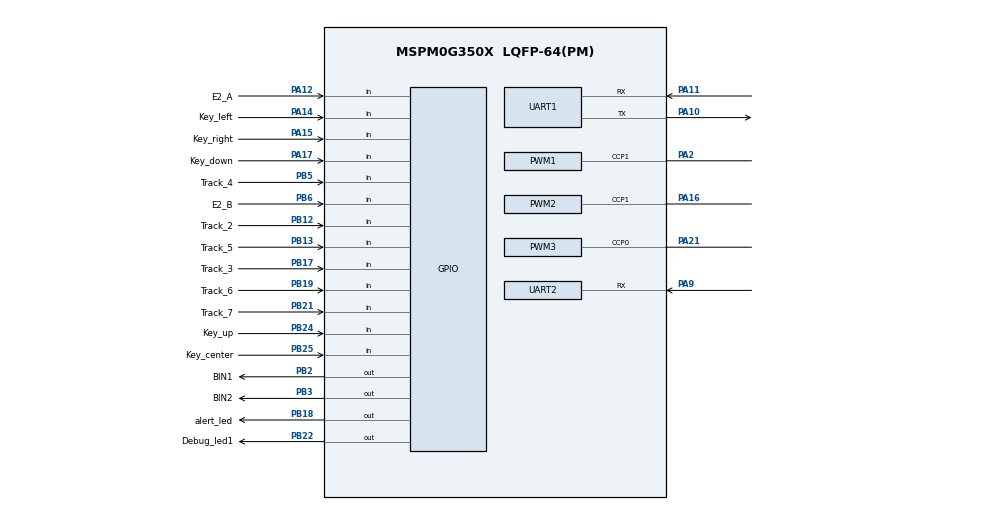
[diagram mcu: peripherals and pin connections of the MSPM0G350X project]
/**
 * @cliArgs --device "MSPM0G350X" --part "Default" --package "LQFP-64(PM)" --product "mspm0_sdk@2.04.00.06"
 * @versions {"tool":"1.23.1+4034"}
 */

/**
 * Import the modules used in this configuration.
 */
const GPIO    = scripting.addModule("/ti/driverlib/GPIO", {}, false);
const GPIO1   = GPIO.addInstance();
const GPIO2   = GPIO.addInstance();
const GPIO3   = GPIO.addInstance();
const GPIO4   = GPIO.addInstance();
const GPIO5   = GPIO.addInstance();
const GPIO6   = GPIO.addInstance();
const PWM     = scripting.addModule("/ti/driverlib/PWM", {}, false);
const PWM1    = PWM.addInstance();
const PWM2    = PWM.addInstance();
const PWM3    = PWM.addInstance();
const SYSCTL  = scripting.addModule("/ti/driverlib/SYSCTL");
const SYSTICK = scripting.addModule("/ti/driverlib/SYSTICK");
const TIMER   = scripting.addModule("/ti/driverlib/TIMER", {}, false);
const TIMER1  = TIMER.addInstance();
const TIMER2  = TIMER.addInstance();
const TIMER3  = TIMER.addInstance();
const TIMER4  = TIMER.addInstance();
const UART    = scripting.addModule("/ti/driverlib/UART", {}, false);
const UART1   = UART.addInstance();
const UART2   = UART.addInstance();

/**
 * Write custom configuration values to the imported modules.
 */
const divider9       = system.clockTree["UDIV"];
divider9.divideValue = 2;

const multiplier2         = system.clockTree["PLL_QDIV"];
multiplier2.multiplyValue = 4;

const mux4       = system.clockTree["EXHFMUX"];
mux4.inputSelect = "EXHFMUX_XTAL";

const mux8       = system.clockTree["HSCLKMUX"];
mux8.inputSelect = "HSCLKMUX_SYSPLL0";

const mux12       = system.clockTree["SYSPLLMUX"];
mux12.inputSelect = "zSYSPLLMUX_HFCLK";

const pinFunction4        = system.clockTree["HFXT"];
pinFunction4.enable       = true;
pinFunction4.HFCLKMonitor = true;
pinFunction4.inputFreq    = 40;
pinFunction4.HFXTStartup  = 10;

GPIO1.$name                              = "Debug_led";
GPIO1.port                               = "PORTB";
GPIO1.associatedPins[0].$name            = "Debug_led1";
GPIO1.associatedPins[0].ioStructure      = "SD";
GPIO1.associatedPins[0].assignedPin      = "22";
GPIO1.associatedPins[0].internalResistor = "PULL_DOWN";
GPIO1.associatedPins[0].pin.$assign      = "PB22";

const Board = scripting.addModule("/ti/driverlib/Board", {}, false);

GPIO2.$name                              = "Debug_key";
GPIO2.associatedPins.create(5);
GPIO2.associatedPins[0].$name            = "Key_center";
GPIO2.associatedPins[0].direction        = "INPUT";
GPIO2.associatedPins[0].ioStructure      = "SD";
GPIO2.associatedPins[0].assignedPort     = "PORTB";
GPIO2.associatedPins[0].assignedPin      = "25";
GPIO2.associatedPins[0].internalResistor = "PULL_UP";
GPIO2.associatedPins[0].invert           = "ENABLE";
GPIO2.associatedPins[0].pin.$assign      = "PB25";
GPIO2.associatedPins[1].invert           = "ENABLE";
GPIO2.associatedPins[1].assignedPort     = "PORTA";
GPIO2.associatedPins[1].direction        = "INPUT";
GPIO2.associatedPins[1].assignedPin      = "14";
GPIO2.associatedPins[1].ioStructure      = "HS";
GPIO2.associatedPins[1].internalResistor = "PULL_UP";
GPIO2.associatedPins[1].$name            = "Key_left";
GPIO2.associatedPins[1].pin.$assign      = "PA14";
GPIO2.associatedPins[2].direction        = "INPUT";
GPIO2.associatedPins[2].ioStructure      = "SD";
GPIO2.associatedPins[2].assignedPort     = "PORTA";
GPIO2.associatedPins[2].assignedPin      = "15";
GPIO2.associatedPins[2].internalResistor = "PULL_UP";
GPIO2.associatedPins[2].invert           = "ENABLE";
GPIO2.associatedPins[2].$name            = "Key_right";
GPIO2.associatedPins[2].pin.$assign      = "PA15";
GPIO2.associatedPins[3].direction        = "INPUT";
GPIO2.associatedPins[3].assignedPort     = "PORTA";
GPIO2.associatedPins[3].assignedPin      = "17";
GPIO2.associatedPins[3].internalResistor = "PULL_UP";
GPIO2.associatedPins[3].invert           = "ENABLE";
GPIO2.associatedPins[3].$name            = "Key_down";
GPIO2.associatedPins[3].pin.$assign      = "PA17";
GPIO2.associatedPins[4].$name            = "Key_up";
GPIO2.associatedPins[4].direction        = "INPUT";
GPIO2.associatedPins[4].internalResistor = "PULL_UP";
GPIO2.associatedPins[4].invert           = "ENABLE";
GPIO2.associatedPins[4].assignedPort     = "PORTB";
GPIO2.associatedPins[4].assignedPin      = "24";
GPIO2.associatedPins[4].ioStructure      = "SD";
GPIO2.associatedPins[4].pin.$assign      = "PB24";

GPIO3.$name                          = "Motor_DIR";
GPIO3.associatedPins.create(4);
GPIO3.associatedPins[0].initialValue = "SET";
GPIO3.associatedPins[0].ioStructure  = "SD";
GPIO3.associatedPins[0].assignedPort = "PORTB";
GPIO3.associatedPins[0].assignedPin  = "15";
GPIO3.associatedPins[0].$name        = "AIN2";
GPIO3.associatedPins[1].initialValue = "SET";
GPIO3.associatedPins[1].assignedPort = "PORTB";
GPIO3.associatedPins[1].assignedPin  = "16";
GPIO3.associatedPins[1].$name        = "AIN1";
GPIO3.associatedPins[2].$name        = "BIN1";
GPIO3.associatedPins[2].initialValue = "SET";
GPIO3.associatedPins[2].ioStructure  = "SD";
GPIO3.associatedPins[2].assignedPort = "PORTB";
GPIO3.associatedPins[2].assignedPin  = "02";
GPIO3.associatedPins[2].pin.$assign  = "PB2";
GPIO3.associatedPins[3].$name        = "BIN2";
GPIO3.associatedPins[3].initialValue = "SET";
GPIO3.associatedPins[3].ioStructure  = "SD";
GPIO3.associatedPins[3].assignedPort = "PORTB";
GPIO3.associatedPins[3].assignedPin  = "03";
GPIO3.associatedPins[3].pin.$assign  = "PB3";

GPIO4.$name                               = "Encoder";
GPIO4.associatedPins.create(4);
GPIO4.associatedPins[0].direction         = "INPUT";
GPIO4.associatedPins[0].assignedPort      = "PORTB";
GPIO4.associatedPins[0].assignedPin       = "23";
GPIO4.associatedPins[0].interruptEn       = true;
GPIO4.associatedPins[0].interruptPriority = "0";
GPIO4.associatedPins[0].polarity          = "RISE";
GPIO4.associatedPins[0].$name             = "E1_B";
GPIO4.associatedPins[1].direction         = "INPUT";
GPIO4.associatedPins[1].assignedPort      = "PORTB";
GPIO4.associatedPins[1].assignedPin       = "27";
GPIO4.associatedPins[1].interruptEn       = true;
GPIO4.associatedPins[1].interruptPriority = "0";
GPIO4.associatedPins[1].polarity          = "RISE";
GPIO4.associatedPins[1].$name             = "E1_A";
GPIO4.associatedPins[2].$name             = "E2_A";
GPIO4.associatedPins[2].direction         = "INPUT";
GPIO4.associatedPins[2].assignedPort      = "PORTA";
GPIO4.associatedPins[2].assignedPin       = "12";
GPIO4.associatedPins[2].interruptEn       = true;
GPIO4.associatedPins[2].interruptPriority = "0";
GPIO4.associatedPins[2].polarity          = "RISE";
GPIO4.associatedPins[2].pin.$assign       = "PA12";
GPIO4.associatedPins[3].$name             = "E2_B";
GPIO4.associatedPins[3].direction         = "INPUT";
GPIO4.associatedPins[3].assignedPort      = "PORTB";
GPIO4.associatedPins[3].assignedPin       = "6";
GPIO4.associatedPins[3].interruptEn       = true;
GPIO4.associatedPins[3].interruptPriority = "0";
GPIO4.associatedPins[3].polarity          = "RISE";
GPIO4.associatedPins[3].pin.$assign       = "PB6";

GPIO5.$name                              = "Track";
GPIO5.port                               = "PORTB";
GPIO5.associatedPins.create(7);
GPIO5.associatedPins[0].direction        = "INPUT";
GPIO5.associatedPins[0].assignedPin      = "04";
GPIO5.associatedPins[0].$name            = "Track_1";
GPIO5.associatedPins[0].internalResistor = "PULL_UP";
GPIO5.associatedPins[1].$name            = "Track_2";
GPIO5.associatedPins[1].direction        = "INPUT";
GPIO5.associatedPins[1].assignedPin      = "12";
GPIO5.associatedPins[1].internalResistor = "PULL_UP";
GPIO5.associatedPins[1].pin.$assign      = "PB12";
GPIO5.associatedPins[2].$name            = "Track_3";
GPIO5.associatedPins[2].direction        = "INPUT";
GPIO5.associatedPins[2].assignedPin      = "17";
GPIO5.associatedPins[2].internalResistor = "PULL_UP";
GPIO5.associatedPins[2].pin.$assign      = "PB17";
GPIO5.associatedPins[3].$name            = "Track_4";
GPIO5.associatedPins[3].direction        = "INPUT";
GPIO5.associatedPins[3].assignedPin      = "5";
GPIO5.associatedPins[3].internalResistor = "PULL_UP";
GPIO5.associatedPins[3].pin.$assign      = "PB5";
GPIO5.associatedPins[4].$name            = "Track_5";
GPIO5.associatedPins[4].direction        = "INPUT";
GPIO5.associatedPins[4].assignedPin      = "13";
GPIO5.associatedPins[4].internalResistor = "PULL_UP";
GPIO5.associatedPins[4].pin.$assign      = "PB13";
GPIO5.associatedPins[5].$name            = "Track_6";
GPIO5.associatedPins[5].direction        = "INPUT";
GPIO5.associatedPins[5].internalResistor = "PULL_DOWN";
GPIO5.associatedPins[5].assignedPin      = "19";
GPIO5.associatedPins[5].pin.$assign      = "PB19";
GPIO5.associatedPins[6].$name            = "Track_7";
GPIO5.associatedPins[6].direction        = "INPUT";
GPIO5.associatedPins[6].assignedPin      = "21";
GPIO5.associatedPins[6].pin.$assign      = "PB21";

GPIO6.$name                          = "Alert_led";
GPIO6.associatedPins[0].$name        = "alert_led";
GPIO6.associatedPins[0].assignedPort = "PORTB";
GPIO6.associatedPins[0].assignedPin  = "18";
GPIO6.associatedPins[0].pin.$assign  = "PB18";

PWM1.ccIndex                            = [1];
PWM1.$name                              = "Motor_A";
PWM1.timerStartTimer                    = true;
PWM1.timerCount                         = 10001;
PWM1.ccp1PinConfig.direction            = scripting.forceWrite("OUTPUT");
PWM1.ccp1PinConfig.hideOutputInversion  = scripting.forceWrite(false);
PWM1.ccp1PinConfig.onlyInternalResistor = scripting.forceWrite(false);
PWM1.ccp1PinConfig.passedPeripheralType = scripting.forceWrite("Digital");
PWM1.ccp1PinConfig.$name                = "ti_driverlib_gpio_GPIOPinGeneric3";
PWM1.peripheral.$assign                 = "TIMG7";
PWM1.peripheral.ccp1Pin.$assign         = "PA2";
PWM1.PWM_CHANNEL_1.$name                = "ti_driverlib_pwm_PWMTimerCC0";
PWM1.PWM_CHANNEL_1.invert               = true;

PWM2.$name                              = "Motor_B";
PWM2.ccIndex                            = [1];
PWM2.timerStartTimer                    = true;
PWM2.timerCount                         = 10001;
PWM2.ccp1PinConfig.direction            = scripting.forceWrite("OUTPUT");
PWM2.ccp1PinConfig.hideOutputInversion  = scripting.forceWrite(false);
PWM2.ccp1PinConfig.onlyInternalResistor = scripting.forceWrite(false);
PWM2.ccp1PinConfig.passedPeripheralType = scripting.forceWrite("Digital");
PWM2.ccp1PinConfig.$name                = "ti_driverlib_gpio_GPIOPinGeneric2";
PWM2.peripheral.$assign                 = "TIMA1";
PWM2.peripheral.ccp1Pin.$assign         = "PA16";
PWM2.PWM_CHANNEL_1.$name                = "ti_driverlib_pwm_PWMTimerCC1";
PWM2.PWM_CHANNEL_1.invert               = true;

PWM3.$name                              = "Debug_Buzzer";
PWM3.ccIndex                            = [0];
PWM3.timerStartTimer                    = true;
PWM3.timerCount                         = 65535;
PWM3.PWM_CHANNEL_0.$name                = "ti_driverlib_pwm_PWMTimerCC2";
PWM3.PWM_CHANNEL_0.invert               = true;
PWM3.ccp0PinConfig.$name                = "ti_driverlib_gpio_GPIOPinGeneric4";
PWM3.ccp0PinConfig.direction            = scripting.forceWrite("OUTPUT");
PWM3.ccp0PinConfig.hideOutputInversion  = scripting.forceWrite(false);
PWM3.ccp0PinConfig.onlyInternalResistor = scripting.forceWrite(false);
PWM3.ccp0PinConfig.passedPeripheralType = scripting.forceWrite("Digital");
PWM3.peripheral.$assign                 = "TIMA0";
PWM3.peripheral.ccp0Pin.$assign         = "PA21";

SYSCTL.forceDefaultClkConfig = true;
SYSCTL.clockTreeEn           = true;

SYSTICK.periodEnable      = true;
SYSTICK.interruptEnable   = true;
SYSTICK.interruptPriority = "0";
SYSTICK.systickEnable     = true;
SYSTICK.period            = 80000;

TIMER1.$name             = "Key_task";
TIMER1.timerPeriod       = "20 ms";
TIMER1.timerStartTimer   = true;
TIMER1.interrupts        = ["ZERO"];
TIMER1.interruptPriority = "3";
TIMER1.timerMode         = "PERIODIC";
TIMER1.timerClkDiv       = 8;

TIMER2.$name             = "PidSpeed_Task";
TIMER2.timerClkDiv       = 8;
TIMER2.timerStartTimer   = true;
TIMER2.interrupts        = ["ZERO"];
TIMER2.interruptPriority = "1";
TIMER2.timerMode         = "PERIODIC";
TIMER2.timerClkPrescale  = 100;
TIMER2.timerPeriod       = "20 ms";

TIMER3.$name             = "PidTrack_Task";
TIMER3.timerMode         = "PERIODIC";
TIMER3.timerPeriod       = "50 ms";
TIMER3.timerClkDiv       = 8;
TIMER3.timerClkPrescale  = 10;
TIMER3.timerStartTimer   = true;
TIMER3.interrupts        = ["ZERO"];
TIMER3.interruptPriority = "1";

TIMER4.$name              = "PidAngle_Task";
TIMER4.timerMode          = "PERIODIC";
TIMER4.timerClkPrescale   = 10;
TIMER4.timerClkDiv        = 8;
TIMER4.timerStartTimer    = true;
TIMER4.interrupts         = ["ZERO"];
TIMER4.interruptPriority  = "1";
TIMER4.timerPeriod        = "50 ms";
TIMER4.peripheral.$assign = "TIMG0";

UART1.$name                            = "Debug_UART";
UART1.enabledInterrupts                = ["RX"];
UART1.peripheral.$assign               = "UART0";
UART1.peripheral.rxPin.$assign         = "PA11";
UART1.peripheral.txPin.$assign         = "PA10";
UART1.txPinConfig.direction            = scripting.forceWrite("OUTPUT");
UART1.txPinConfig.hideOutputInversion  = scripting.forceWrite(false);
UART1.txPinConfig.onlyInternalResistor = scripting.forceWrite(false);
UART1.txPinConfig.passedPeripheralType = scripting.forceWrite("Digital");
UART1.txPinConfig.$name                = "ti_driverlib_gpio_GPIOPinGeneric0";
UART1.rxPinConfig.hideOutputInversion  = scripting.forceWrite(false);
UART1.rxPinConfig.onlyInternalResistor = scripting.forceWrite(false);
UART1.rxPinConfig.passedPeripheralType = scripting.forceWrite("Digital");
UART1.rxPinConfig.$name                = "ti_driverlib_gpio_GPIOPinGeneric1";

UART2.$name                            = "Rx_yaw";
UART2.targetBaudRate                   = 115200;
UART2.direction                        = "RX";
UART2.enabledInterrupts                = ["RX"];
UART2.interruptPriority                = "2";
UART2.rxPinConfig.hideOutputInversion  = scripting.forceWrite(false);
UART2.rxPinConfig.onlyInternalResistor = scripting.forceWrite(false);
UART2.rxPinConfig.passedPeripheralType = scripting.forceWrite("Digital");
UART2.rxPinConfig.$name                = "ti_driverlib_gpio_GPIOPinGeneric6";
UART2.peripheral.$assign               = "UART1";
UART2.peripheral.rxPin.$assign         = "PA9";

/**
 * Pinmux solution for unlocked pins/peripherals. This ensures that minor changes to the automatic solver in a future
 * version of the tool will not impact the pinmux you originally saw.  These lines can be completely deleted in order to
 * re-solve from scratch.
 */
pinFunction4.peripheral.$suggestSolution           = "SYSCTL";
pinFunction4.peripheral.hfxInPin.$suggestSolution  = "PA5";
pinFunction4.peripheral.hfxOutPin.$suggestSolution = "PA6";
Board.peripheral.$suggestSolution                  = "DEBUGSS";
Board.peripheral.swclkPin.$suggestSolution         = "PA20";
Board.peripheral.swdioPin.$suggestSolution         = "PA19";
GPIO3.associatedPins[0].pin.$suggestSolution       = "PB15";
GPIO3.associatedPins[1].pin.$suggestSolution       = "PB16";
GPIO4.associatedPins[0].pin.$suggestSolution       = "PB23";
GPIO4.associatedPins[1].pin.$suggestSolution       = "PB27";
GPIO5.associatedPins[0].pin.$suggestSolution       = "PB4";
TIMER1.peripheral.$suggestSolution                 = "TIMG12";
TIMER2.peripheral.$suggestSolution                 = "TIMG8";
TIMER3.peripheral.$suggestSolution                 = "TIMG6";
